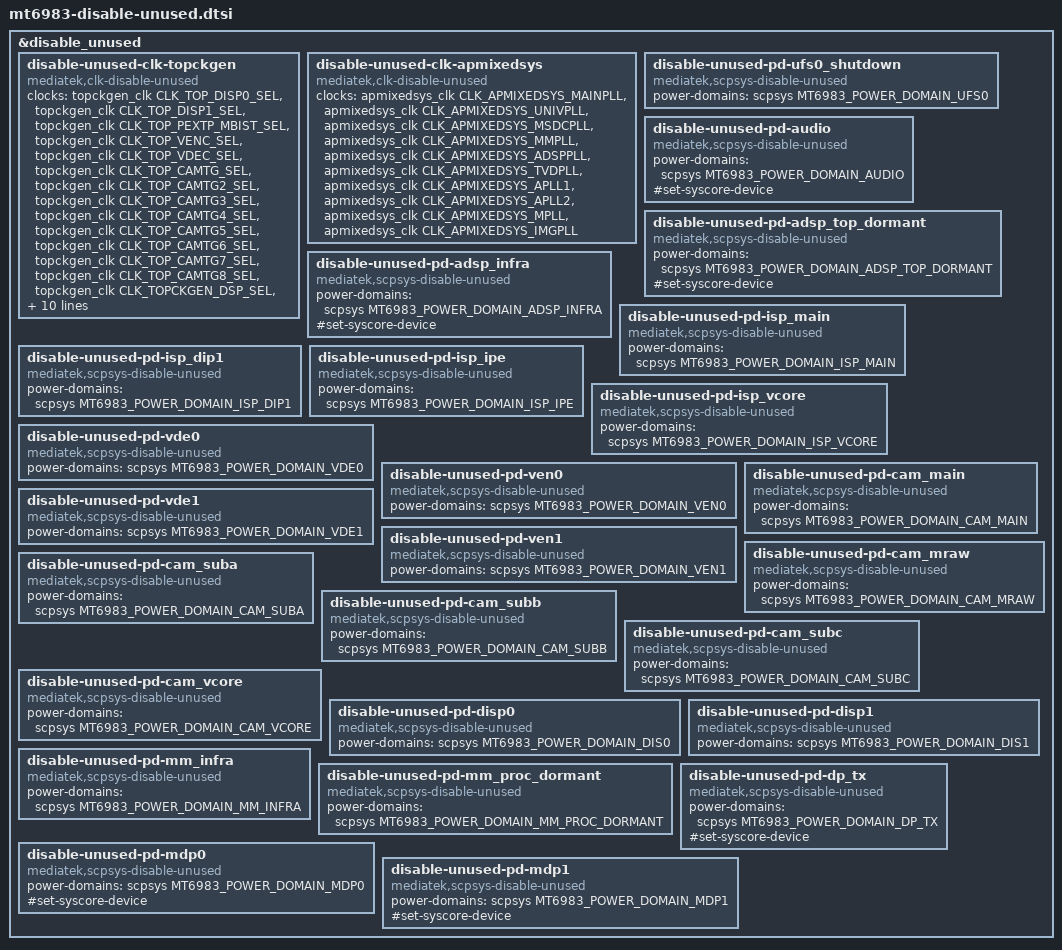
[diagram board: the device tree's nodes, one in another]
// SPDX-License-Identifier: (GPL-2.0 OR MIT)
/*
 * Copyright (C) 2021 MediaTek Inc.
 * Author: Owen Chen <owen.chen@mediatek.com>
 */

&disable_unused {
	status = "okay";

	disable-unused-clk-topckgen {
		compatible = "mediatek,clk-disable-unused";
		clocks =
			<&topckgen_clk CLK_TOP_DISP0_SEL>,
			<&topckgen_clk CLK_TOP_DISP1_SEL>,
			<&topckgen_clk CLK_TOP_PEXTP_MBIST_SEL>,
			<&topckgen_clk CLK_TOP_VENC_SEL>,
			<&topckgen_clk CLK_TOP_VDEC_SEL>,
			<&topckgen_clk CLK_TOP_CAMTG_SEL>,
			<&topckgen_clk CLK_TOP_CAMTG2_SEL>,
			<&topckgen_clk CLK_TOP_CAMTG3_SEL>,
			<&topckgen_clk CLK_TOP_CAMTG4_SEL>,
			<&topckgen_clk CLK_TOP_CAMTG5_SEL>,
			<&topckgen_clk CLK_TOP_CAMTG6_SEL>,
			<&topckgen_clk CLK_TOP_CAMTG7_SEL>,
			<&topckgen_clk CLK_TOP_CAMTG8_SEL>,
			<&topckgen_clk CLK_TOPCKGEN_DSP_SEL>,
			<&topckgen_clk CLK_TOPCKGEN_DSP1_SEL>,
			<&topckgen_clk CLK_TOPCKGEN_DSP2_SEL>,
			<&topckgen_clk CLK_TOPCKGEN_DSP3_SEL>,
			<&topckgen_clk CLK_TOPCKGEN_DSP4_SEL>,
			<&topckgen_clk CLK_TOPCKGEN_DSP5_SEL>,
			<&topckgen_clk CLK_TOPCKGEN_DSP6_SEL>,
			<&topckgen_clk CLK_TOPCKGEN_DSP7_SEL>,
			<&topckgen_clk CLK_TOPCKGEN_IPU_IF_SEL>,
			<&topckgen_clk CLK_TOPCKGEN_UFS_SEL>,
			<&topckgen_clk CLK_TOPCKGEN_CAMTM_SEL>;
	};

	disable-unused-clk-apmixedsys {
		compatible = "mediatek,clk-disable-unused";
		clocks =
			<&apmixedsys_clk CLK_APMIXEDSYS_MAINPLL>,
			<&apmixedsys_clk CLK_APMIXEDSYS_UNIVPLL>,
			<&apmixedsys_clk CLK_APMIXEDSYS_MSDCPLL>,
			<&apmixedsys_clk CLK_APMIXEDSYS_MMPLL>,
			<&apmixedsys_clk CLK_APMIXEDSYS_ADSPPLL>,
			<&apmixedsys_clk CLK_APMIXEDSYS_TVDPLL>,
			<&apmixedsys_clk CLK_APMIXEDSYS_APLL1>,
			<&apmixedsys_clk CLK_APMIXEDSYS_APLL2>,
			<&apmixedsys_clk CLK_APMIXEDSYS_MPLL>,
			<&apmixedsys_clk CLK_APMIXEDSYS_IMGPLL>;
	};

	disable-unused-pd-ufs0_shutdown {
		compatible = "mediatek,scpsys-disable-unused";
		power-domains = <&scpsys MT6983_POWER_DOMAIN_UFS0>;
	};

	disable-unused-pd-audio {
		compatible = "mediatek,scpsys-disable-unused";
		power-domains = <&scpsys MT6983_POWER_DOMAIN_AUDIO>;
		#set-syscore-device;
	};

	disable-unused-pd-adsp_top_dormant {
		compatible = "mediatek,scpsys-disable-unused";
		power-domains = <&scpsys MT6983_POWER_DOMAIN_ADSP_TOP_DORMANT>;
		#set-syscore-device;
	};

	disable-unused-pd-adsp_infra {
		compatible = "mediatek,scpsys-disable-unused";
		power-domains = <&scpsys MT6983_POWER_DOMAIN_ADSP_INFRA>;
		#set-syscore-device;
	};

	disable-unused-pd-isp_main {
		compatible = "mediatek,scpsys-disable-unused";
		power-domains = <&scpsys MT6983_POWER_DOMAIN_ISP_MAIN>;
	};

	disable-unused-pd-isp_dip1 {
		compatible = "mediatek,scpsys-disable-unused";
		power-domains = <&scpsys MT6983_POWER_DOMAIN_ISP_DIP1>;
	};

	disable-unused-pd-isp_ipe {
		compatible = "mediatek,scpsys-disable-unused";
		power-domains = <&scpsys MT6983_POWER_DOMAIN_ISP_IPE>;
	};

	disable-unused-pd-isp_vcore {
		compatible = "mediatek,scpsys-disable-unused";
		power-domains = <&scpsys MT6983_POWER_DOMAIN_ISP_VCORE>;
	};

	disable-unused-pd-vde0 {
		compatible = "mediatek,scpsys-disable-unused";
		power-domains = <&scpsys MT6983_POWER_DOMAIN_VDE0>;
	};

	disable-unused-pd-ven0 {
		compatible = "mediatek,scpsys-disable-unused";
		power-domains = <&scpsys MT6983_POWER_DOMAIN_VEN0>;
	};

	disable-unused-pd-vde1 {
		compatible = "mediatek,scpsys-disable-unused";
		power-domains = <&scpsys MT6983_POWER_DOMAIN_VDE1>;
	};

	disable-unused-pd-ven1 {
		compatible = "mediatek,scpsys-disable-unused";
		power-domains = <&scpsys MT6983_POWER_DOMAIN_VEN1>;
	};

	disable-unused-pd-cam_main {
		compatible = "mediatek,scpsys-disable-unused";
		power-domains = <&scpsys MT6983_POWER_DOMAIN_CAM_MAIN>;
	};

	disable-unused-pd-cam_mraw {
		compatible = "mediatek,scpsys-disable-unused";
		power-domains = <&scpsys MT6983_POWER_DOMAIN_CAM_MRAW>;
	};

	disable-unused-pd-cam_suba {
		compatible = "mediatek,scpsys-disable-unused";
		power-domains = <&scpsys MT6983_POWER_DOMAIN_CAM_SUBA>;
	};

	disable-unused-pd-cam_subb {
		compatible = "mediatek,scpsys-disable-unused";
		power-domains = <&scpsys MT6983_POWER_DOMAIN_CAM_SUBB>;
	};

	disable-unused-pd-cam_subc {
		compatible = "mediatek,scpsys-disable-unused";
		power-domains = <&scpsys MT6983_POWER_DOMAIN_CAM_SUBC>;
	};

	disable-unused-pd-cam_vcore {
		compatible = "mediatek,scpsys-disable-unused";
		power-domains = <&scpsys MT6983_POWER_DOMAIN_CAM_VCORE>;
	};

	disable-unused-pd-disp0 {
		compatible = "mediatek,scpsys-disable-unused";
		power-domains = <&scpsys MT6983_POWER_DOMAIN_DIS0>;
	};

	disable-unused-pd-disp1 {
		compatible = "mediatek,scpsys-disable-unused";
		power-domains = <&scpsys MT6983_POWER_DOMAIN_DIS1>;
	};

	disable-unused-pd-mm_infra {
		compatible = "mediatek,scpsys-disable-unused";
		power-domains = <&scpsys MT6983_POWER_DOMAIN_MM_INFRA>;
	};

	disable-unused-pd-mm_proc_dormant {
		compatible = "mediatek,scpsys-disable-unused";
		power-domains = <&scpsys MT6983_POWER_DOMAIN_MM_PROC_DORMANT>;
	};

	disable-unused-pd-dp_tx {
		compatible = "mediatek,scpsys-disable-unused";
		power-domains = <&scpsys MT6983_POWER_DOMAIN_DP_TX>;
		#set-syscore-device;
	};

	disable-unused-pd-mdp0 {
		compatible = "mediatek,scpsys-disable-unused";
		power-domains = <&scpsys MT6983_POWER_DOMAIN_MDP0>;
		#set-syscore-device;
	};

	disable-unused-pd-mdp1 {
		compatible = "mediatek,scpsys-disable-unused";
		power-domains = <&scpsys MT6983_POWER_DOMAIN_MDP1>;
		#set-syscore-device;
	};
};
